# w600 register map
File version: v0.1
Registers are 32-bit, read-write, reset 0x0 unless marked. A register's access mark holds for its fields unless they carry their own. Offsets are from the block's base; [hi:lo] are bit positions; 'fields as' and 'values as' point back to an identical list.

## pwm
Base 0x40011800
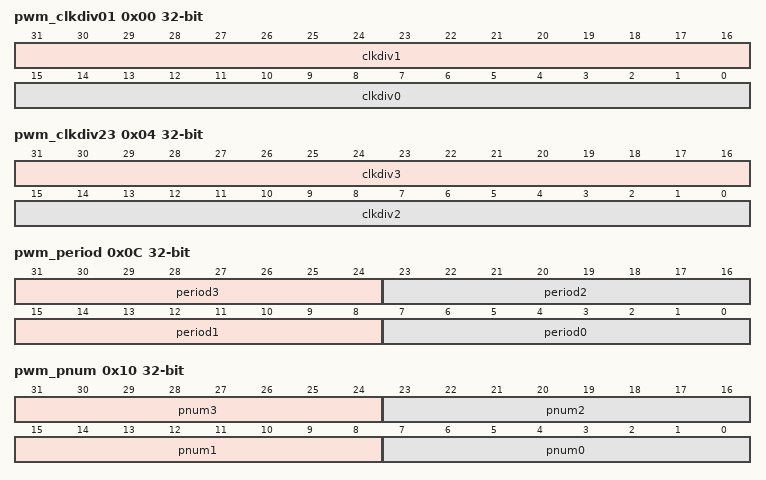
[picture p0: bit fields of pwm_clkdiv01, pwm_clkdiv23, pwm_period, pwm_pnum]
0x00 pwm_clkdiv01 — 对通道 0 和通道 1 的时钟进行分频
  [31:16] clkdiv1 — CH1 分频计数器 由计数器值决定分频数 注意：分频范围为(0~65535)，如不需要分频，输入 0 或 1。
  [15:0] clkdiv0 — CH0 分频计数器同CH1
0x04 pwm_clkdiv23 — 对通道 2 和通道 3 的时钟进行分频
  [31:16] clkdiv3 — CH3 分频计数器同CH1
  [15:0] clkdiv2 — CH2 分频计数器同CH1
0x08 pwm_ctl — 用以配置或者控制一些可配置项
  [31:27] cnten — 计数器计数使能 注意：每位分别控制每个通道，从高到低依次控制CH4、CH3、CH2、CH1 和CH0
    0=停止计数; 1=开始计数
  [23:22] cnttype3 — CH3 计数器计数方式 注意：在PWM 模式下，当计数器被设置为沿对齐模式时，需要设置计数方式为递减方式。
    0=边缘对齐模式（计数器计数方式为递增，仅针对捕获模式）; 1=边缘对齐模式（计数器计数方式为递减，仅针对 PWM 模式）; 2=中央对齐模式（仅针对 PWM 模式）
  [21:20] cnttype2 — CH2 计数器计数方式同CH3
  [19:18] cnttype1 — CH1 计数器计数方式同CH3
  [17:16] cnttype0 — CH0 计数器计数方式同CH3
  [15:14] twosyncen — 2 通道同步模式使能信号 PWM_CH0 和PWM_CH1 具有相同的相位，且相位由 PWM_CH0 决定；PWM_CH2和PWM_CH3 具有相同的相位，且相位由PWM_CH2 决定 15bit 控制CH3 和CH2 14bit 控制CH1 和CH0
    0=不允许 2 通道同步; 1=允许 2 通道同步，
  [11:8] cntmode — PWM 生成循环方式 注意：CNTMODE 变化过程中，PWM_CMPDAT 归零；每位分别控制每个通道，从高到低依次控制PW3、PW2、PW1 和PW0
    0=单次模式; 1=自动装载模式
  [5:2] pinv — PWM 输出信号极性使能 注意：每位分别控制每个通道，从高到低依次控制PW3、PW2、PW1 和PW0
    0=PWM 输出极性翻转不使能; 1=PWM 输出极性翻转使能
  [0] reserved — 保留
  [0] capinv — 捕获反向使能标识位
    0=捕获模式输入信号反向无效; 1=捕获模式输入信号反向有效，对输入信号取反
  [0] cpen — 捕获功能使能标识位
    0=CH0 捕获功能无效，RCAPDAT 和FCAPDAT 值不会被更新；; 1=CH0 捕获功能有效，捕获并锁存 PWM 计数器，分别存储在 RCAPDAT（上升沿锁存）和FCAPDAT（下降沿锁存）
  [0] reserved — 保留
  [0] poen — PWM 管脚输出使能位
    0=PWM 管脚置为输出状态; 1=PWM 管脚置为三态状态注意只是针对CH0
  [0] reserved — 保留
  [0] allsyncen — 全通道同步模式使能信号
    0=不允许全部通道同步; 1=允许全部通道同步，PWM_CH0、PWM_CH1、PWM_CH2 和 PWM_CH3 具有相同的相位，且相位由PWM_CH0 决定
  [1:0] outmode — 输出模式 BIT0 控制CH0 和CH1
    0=每两个通道非互补模式; 1=每两个通道组成互补模式 BIT1 控制CH2 和CH3
0x0C pwm_period — 用以设置通道 0 至通道 4 的周期
  [31:24] period3 — CH3 周期寄存器值(注意：period 不可以大于 255) “沿对齐模式（计数器计数方式为递减）”： 寄存器值，周期值为（PERIOD + 1） 占空比=（CMP+1）/（PERIOD + 1） CMP>=PERIOD：PWM 输出固定为高 CMP<PERIOD：PWM 低电平宽度为（PERIOD-CMP），高电平宽度为（CMP+1） CMP=0：PWM 低电平宽度为PERIOD，高电平宽度为 1； “中间对齐模式”： PERIOD 寄存器值：周期为 2*（PERIOD+1） 占空比=(2*CMP+1）/（2*（PERIOD+1）） CMP>PERIOD：PWM 持续为高 CMP<=PERIOD：PWM 低电平=2*（PERIOD-CMP）+1，高电平=（2*CMP）+1 CMP=0：PWM 低电平宽度为 2*PERIOD+1，高电平宽度为 1。注意：“中间对齐模式”中，周期数不应为 255。 无论选择哪种对齐模式，通道周期均由分频数（N）和周期数（P）共同决定，即：输入时钟为 40MHz，经分频后时钟频率f_div 为：f_div = 40MHz/N，N 为分频数（16bit）。输出频率 f_output 为：f_output = f_div / P，P 为周期数。 注意：在PWM 模式下，当计数器被设置为沿对齐模式时，需要设置计数方式为递 减方式。
  [23:16] period2 — CH2 周期寄存器值(注意：period 不可以大于 255) 同PERIOD3
  [15:8] period1 — CH1 周期寄存器值(注意：period 不可以大于 255) 同PERIOD3
  [7:0] period0 — CH0 周期寄存器值(注意：period 不可以大于 255) 同PERIOD3
0x10 pwm_pnum — 用以设置通道 0 至通道 4 的信号生 成周期数
  [31:24] pnum3 — PWM3 生成周期数 设置 PWM3 周期数 PNUM3，当 PWM 产生PNUM3 个 PWM 信号后，停止生成信号，同时触发中断和置位中断状态字
  [23:16] pnum2 — PWM2 生成周期数同PNUM3
  [15:8] pnum1 — PWM1 生成周期数同PNUM3
  [7:0] pnum0 — PWM0 生成周期数同PNUM3
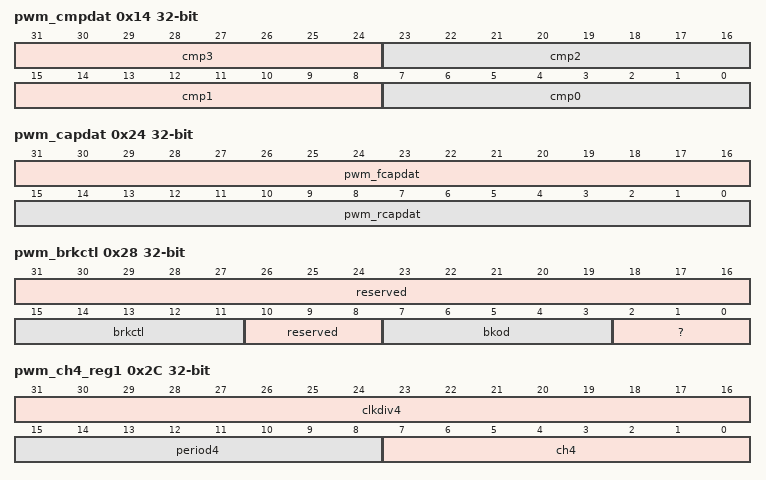
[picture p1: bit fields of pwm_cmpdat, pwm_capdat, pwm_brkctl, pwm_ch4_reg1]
0x14 pwm_cmpdat — 用以存放通道 0 至通道 4 的比较值 以产生不同的占空比
  [31:24] cmp3 — PWM3 比较寄存器值 “沿对齐模式（计数器计数方式为递减）”： PERIOD 寄存器值，周期值为（PERIOD + 1） 占空比=（CMP+1）/（PERIOD + 1） CMP>=PERIOD：PWM 输出固定位高 CMP<PERIOD：PWM 低电平宽度为（PERIOD-CMP），高电平宽度为（CMP+1） CMP=0：PWM 低电平宽度为PERIOD，高电平宽度为 1； “中间对齐模式”： PERIOD 寄存器值：周期为 2*（PERIOD+1） 占空比=(2*CMP+1）/2*（PERIOD+1） CMP>PERIOD：PWM 持续为高 CMP<=PERIOD：PWM 低电平=2*（PERIOD-CMP）+1，高电平=（2*CMP）+1 CMP=0：PWM 低电平宽度为 2*PERIOD+1，高电平宽度为 1。 无论选择哪种对齐模式，通道周期均由分频数（N）和周期数（P）共同决定，即：输入时钟为 40MHz，经分频后时钟频率 f_div 为：f_div = 40MHz/N，N 为分频数 （16bit）。输出频率 f_output 为：f_output = f_div / P，P 为周期数。 注意：在PWM 模式下，当计数器被设置为沿对齐模式时，需要设置计数方式为递减方式。
  [23:16] cmp2 — PWM2 比较寄存器值同CMP3
  [15:8] cmp1 — PWM1 比较寄存器值同CMP3
  [7:0] cmp0 — PWM0 比较寄存器值同CMP3
0x18 pwm_dtctl — 用以配置或者控制死区相关的可配 置项
  [31:22] reserved — 保留
  [19:18] reserved — 保留
  [17:16] dtdiv — 死区时钟分频控制
    0=死区时钟等于基准时钟（40MHz）; 1=死区时钟等于基准时钟（40MHz）二分频; 2=死区时钟等于基准时钟（40MHz）四分频; 3=死区时钟等于基准时钟（40MHz）八分频
  [15:8] dtcnt23 — 通道 3 和通道 2 的死区间隔 8bit 决定死区间隔值，死区时钟由DTDIV 决定
  [0] dten23 — 通道 2 和通道 3 是否可以插入死区有效标识 插入死区有效信号只有在通道的互补模式打开后，才有效。并且，如果插入有效信号为 0，则两个通道输出的互补信号没有死区的插入
    0=插入死区无效; 1=插入死区有效
  [0] dten01 — 通道 0 和通道 1 是否可以插入死区有效标识同DTEN23
  [7:0] dtcnt01 — 通道 1 和通道 0 的死区间隔 8bit 决定死区间隔值，死区时钟由DTDIV 决定
0x1C pwm_inten — 用以对相关中断进行使能控制
  [31:8] reserved — 保留
  [0] dma_request_en — DMA_request 使能
    0=DMA_request 无效; 1=DMA_request 有效
  [0] flien — 下降沿缓存中断使能位
    0=下降沿缓存中断无效; 1=下降沿缓存中断有效注意针对CH0 而言
  [0] rlien — 上升沿缓存中断使能位
    0=上升缓存中断无效; 1=上升沿缓存中断有效注意针对CH0 而言
  [4:0] pien — PWM 周期中断使能位 注意：当计数器计数到 0，且 PWM 周期个数满足PWM_PNUM 后，触发中断。
    0=周期中断无效; 1=周期中断有效
0x20 pwm_intsts — 用以查询相关中断的状态
  [31:10] reserved — 保留
  [0] overfl — 计数器溢出标志 注意：当用户清除CFLIF 或CRLIF 时，本bit 也同时被清除
    0=捕获模式，计数器计数过程中，计数器未溢出; 1=捕获模式，计数器计数过程中，计数器溢出
  [0] flifov — 下降沿延迟中断标识过跑状态
    0=当CFILF 为 1 时，无下降沿延迟中断产生; 1=当CFILF 为 1 时，又一次发生下降沿延迟中断注意当用户清除CFILF 时，本bit 也同时被清除
  [0] rlifov — 上升沿延迟中断标识过跑状态 注意：当用户清除CRILF 时，本bit 也同时被清除
    0=当CRILF 为 1 时，无上升沿延迟中断产生; 1=当CRILF 为 1 时，又一次发生上升沿延迟中断
  [0] cflif — 捕获下降沿中断标识 注意：通过写入 1，清除该标识位；注意：针对CH0 而言
    0=没有捕获到下降沿; 1=当捕获到下降沿，本位被设置为 1
  [0] crlif — 捕获上升沿中断标识 注意：通过写入 1，清除该标识位；注意：针对CH0 而言
    0=没有捕获到上升沿; 1=当捕获到上升沿，本位被设置为 1
  [4:0] pif — PWM 周期中断标识 当PWM 产生指定周期PWM 信号后，该标识位置 1；通过软件写入 1，清除该标识注意：每位分别标识每个通道，从高到低依次控制 PW4、PW3、PW2、PW1 和PW0
0x24 pwm_capdat ro — 用以捕获并计数来到通道 0 的上升 沿和下降沿
  [31:16] pwm_fcapdat — 捕获下降沿寄存器 当输入信号存在下降沿时，存储当前计数器值
  [15:0] pwm_rcapdat — 捕获上升沿寄存器 当输入信号存在上升沿时，存储当前计数器值
0x28 pwm_brkctl — 用以对制动模式进行控制
  [31:16] reserved — 保留
  [15:11] brkctl — 制动模式使能 [7:3]分别对应CH4、CH3、CH2、CH1 和CH0
    0=制动模式禁止; 1=制动模式启动
  [10:8] reserved — 保留
  [7:3] bkod — 制动输出控制寄存器 [7:3]分别对应CH4、CH3、CH2、CH1 和CH0
    0=当制动模式有效时，PWM 输出低电平; 1=当制动模式有效时，PWM 输出高电平
  [2:0] ? — 保留
0x2C pwm_ch4_reg1 — 对通道 4 的时钟进行分频
  [31:16] clkdiv4 — CH4 分频计数器 由计数器值决定分频数 注意：分频范围为(0~65535)，如不需要分频，输入 0 或 1。
  [15:8] period4 — CH4 周期寄存器值(注意：period 不可以大于 255) “沿对齐模式（计数器计数方式为递减）”： PERIOD 寄存器值，周期值为（PERIOD + 1） 占空比=（CMP+1）/（PERIOD + 1） CMP>=PERIOD：PWM 输出固定位高 CMP<PERIOD：PWM 低电平宽度为（PERIOD-CMP），高电平宽度为（CMP+1） CMP=0：PWM 低电平宽度为PERIOD，高电平宽度为 1； “中间对齐模式”： PERIOD 寄存器值：周期为 2*（PERIOD+1） 占空比=(2*CMP+1）/（2*（PERIOD+1）） CMP>PERIOD：PWM 持续为高 CMP<=PERIOD：PWM 低电平=2*（PERIOD-CMP）+1，高电平=（2*CMP）+1 CMP=0：PWM 低电平宽度为 2*PERIOD+1，高电平宽度为 1。注意：“中间对齐模式”中，周期数不应为 255。 无论选择哪种对齐模式，通道周期均由分频数（N）和周期数（P）共同决定， 即：输入时钟为 40MHz，经分频后时钟频率f_div 为：f_div = 40MHz/N，N 为分频数（16bit）。输出频率 f_output 为：f_output = f_div / P，P 为周期数。 注意：在PWM 模式下，当计数器被设置为沿对齐模式时，需要设置计数方式为递 减方式。
  [7:0] ch4 — 生成周期数 设置PWM4 周期数为PNUM4，当PWM 产生PNUM4 个PWM 信号后，停止生成信号，同时触发中断和置位中断状态字
0x30 pwm_ch4_reg2 — 对通道 4 的相关配置项进行设置
  [31:16] reserved — 保留
  [15:8] cmp4 — CH4 周期寄存器值 “沿对齐模式（计数器计数方式为递减）”： PERIOD 寄存器值，周期值为（PERIOD + 1） 占空比=（CMP+1）/（PERIOD + 1） CMP>=PERIOD：PWM 输出固定位高 CMP<PERIOD：PWM 低电平宽度为（PERIOD-CMP），高电平宽度为（CMP+1） CMP=0：PWM 低电平宽度为PERIOD，高电平宽度为 1； “中间对齐模式”： PERIOD 寄存器值：周期为 2*（PERIOD+1） 占空比=(2*CMP+1）/2*（PERIOD+1） CMP>PERIOD：PWM 持续为高 CMP<=PERIOD：PWM 低电平=2*（PERIOD-CMP）+1，高电平=（2*CMP）+1 CMP=0：PWM 低电平宽度为 2*PERIOD+1，高电平宽度为 1。 无论选择哪种对齐模式，通道周期均由分频数（N）和周期数（P）共同决定，即：输入时钟为 40MHz，经分频后时钟频率 f_div 为：f_div = 40MHz/N，N 为分频数 （16bit）。输出频率 f_output 为：f_output = f_div / P，P 为周期数。 注意：在PWM 模式下，当计数器被设置为沿对齐模式时，需要设置计数方式为递减方式。
  [7:5] reserved — 保留
  [4:3] cnttype4 — CH4 计数器计数方式 注意：在PWM 模式下，当计数器被设置为沿对齐模式时，需要设置计数方式为递减方式。
    0=边缘对齐模式（计数器计数方式为递增，仅针对捕获模式）; 1=边缘对齐模式（计数器计数方式为递减，仅针对PWM 模式）; 2=中央对齐模式（仅针对PWM 模式）
  [0] reserved — 保留
  [0] cntmode4 — CH4 生成循环方式 注意：CNTMODE 变化过程中，PWM_CMPDAT 归零
    0=单次模式; 1=自动装载模式
  [0] pinv4 — CH4 输出信号极性使能
    0=PWM 输出极性翻转不使能; 1=PWM 输出极性翻转使能
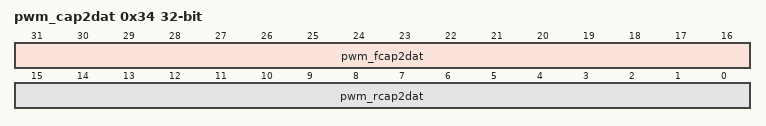
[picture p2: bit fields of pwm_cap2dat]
0x34 pwm_cap2dat ro — 用以捕获并计数来到通道 4 的上升 沿和下降沿
  [31:16] pwm_fcap2dat — 捕获下降沿寄存器 当输入信号存在下降沿时，存储当前计数器值
  [15:0] pwm_rcap2dat — 捕获上升沿寄存器 当输入信号存在上升沿时，存储当前计数器值
0x38 pwm_cap2ctl — 通道 4 的相关配置项进行设置
  [31:11] reserved — 保留
  [0] dma_request2_mask — 注意：只是针对CH4
    0=DMA_request2 无效; 1=DMA_request2 有效
  [0] flien2 — 下降沿缓存中断使能位
    0=下降沿缓存中断无效; 1=下降沿缓存中断有效注意只是针对CH4
  [0] rlien2 — 上升沿缓存中断使能位
    0=上升缓存中断无效; 1=上升沿缓存中断有效注意只是针对CH4
  [0] overfl2 — 计数器溢出标志 注意：当用户清除CFLIF 或CRLIF 时，本bit 也同时被清除注意：只是针对CH4
    0=捕获模式，计数器计数过程中，计数器未溢出; 1=捕获模式，计数器计数过程中，计数器溢出
  [0] flifov2 — 下降沿延迟中断标识过跑状态 注意：只是针对CH4
    values as pwm_intsts.flifov
  [0] rlifov2 — 上升沿延迟中断标识过跑状态 注意：当用户清除CRILF 时，本bit 也同时被清除注意：只是针对CH4
    0=当CRILF 为 1 时，无上升沿延迟中断产生; 1=当CRILF 为 1 时，又一次发生上升沿延迟中断
  [0] cflif2 — 捕获下降沿中断标识 注意：通过写入 1，清除该标识位注意：只是针对CH4
    0=没有捕获到下降沿; 1=当捕获到下降沿，本位被设置为 1
  [0] crlif2 — 捕获上升沿中断标识 注意：通过写入 1，清除该标识位注意：只是针对CH4
    0=没有捕获到上升沿; 1=当捕获到上升沿，本位被设置为 1
  [0] poen2 — PWM 管脚输出使能位
    0=PWM 管脚置为输出状态; 1=PWM 管脚置为三态状态注意只是针对CH4
  [0] cpen2 — 捕获功能使能标识位 注意：只是针对CH4
    0=CH4 捕获功能无效，RCAPDAT 和FCAPDAT 值不会被更新；; 1=CH4 捕获功能有效，捕获并锁存 PWM 计数器，分别存储在 RCAPDAT（上升沿锁存）和FCAPDAT（下降沿锁存）
  [0] capinv2 — 捕获反向使能标识位
    0=捕获模式输入信号反向无效; 1=捕获模式输入信号反向有效，对输入信号取反注意只是针对CH4
